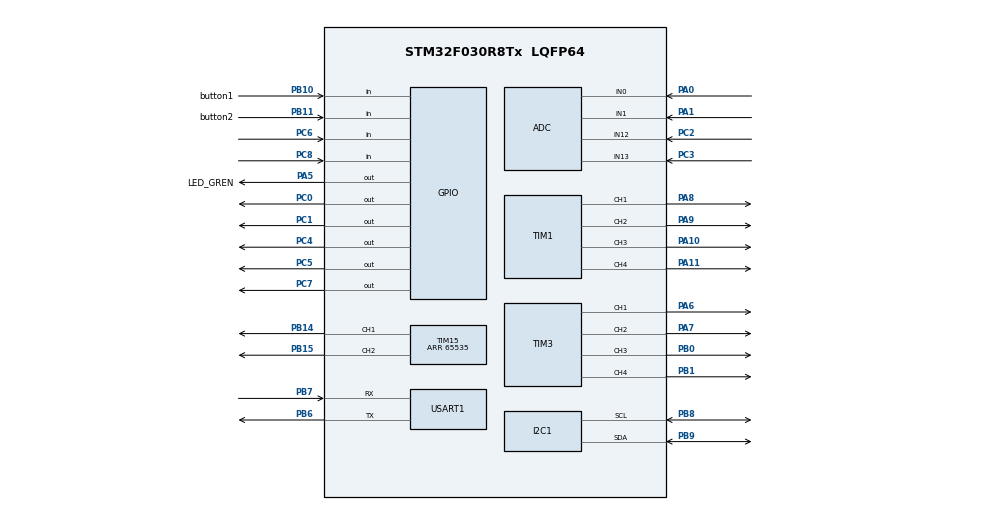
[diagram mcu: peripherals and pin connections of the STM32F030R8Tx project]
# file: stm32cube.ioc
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FREERTOS.Tasks01=task_1,24,128,task_1_function,Default,NULL,Dynamic,NULL,NULL;task_2,16,128,task_2_function,Default,NULL,Dynamic,NULL,NULL
Mcu.Family=STM32F0
Mcu.Name=STM32F030R8Tx
Mcu.Package=LQFP64
NVIC.TIM6_IRQn=true\:3\:0\:false\:false\:true\:false\:false\:true\:true
NVIC.TimeBase=TIM6_IRQn
NVIC.TimeBaseIP=TIM6
PA0.Mode=IN0
PA0.Signal=ADC_IN0
PA1.Mode=IN1
PA1.Signal=ADC_IN1
PA10.Signal=S_TIM1_CH3
PA11.Signal=S_TIM1_CH4
PA13.Mode=Serial_Wire
PA13.Signal=SYS_SWDIO
PA14.Mode=Serial_Wire
PA14.Signal=SYS_SWCLK
PA2.Signal=USART2_TX
PA3.Signal=USART2_RX
PA5.GPIO_Label=LED_GREN
PA5.Signal=GPIO_Output
PA6.Signal=S_TIM3_CH1
PA7.Signal=S_TIM3_CH2
PA8.Signal=S_TIM1_CH1
PA9.Signal=S_TIM1_CH2
PB0.Signal=S_TIM3_CH3
PB1.Signal=S_TIM3_CH4
PB10.GPIO_Label=button1
PB10.Signal=GPIO_Input
PB11.GPIO_Label=button2
PB11.Signal=GPIO_Input
PB14.Signal=S_TIM15_CH1
PB15.Signal=S_TIM15_CH2
PB6.Mode=Asynchronous
PB6.Signal=USART1_TX
PB7.Mode=Asynchronous
PB7.Signal=USART1_RX
PB8.Mode=I2C
PB8.Signal=I2C1_SCL
PB9.Mode=I2C
PB9.Signal=I2C1_SDA
PC0.Signal=GPIO_Output
PC1.Signal=GPIO_Output
PC2.Mode=IN12
PC2.Signal=ADC_IN12
PC3.Mode=IN13
PC3.Signal=ADC_IN13
PC4.Signal=GPIO_Output
PC5.Signal=GPIO_Output
PC6.Signal=GPIO_Input
PC7.Signal=GPIO_Output
PC8.Signal=GPIO_Input
ProjectManager.HeapSize=0x200
ProjectManager.StackSize=0x400
ProjectManager.TargetToolchain=Makefile
SH.S_TIM15_CH1.0=TIM15_CH1,PWM Generation1 CH1
SH.S_TIM15_CH2.0=TIM15_CH2,PWM Generation2 CH2
SH.S_TIM1_CH1.0=TIM1_CH1,PWM Generation1 CH1
SH.S_TIM1_CH2.0=TIM1_CH2,PWM Generation2 CH2
SH.S_TIM1_CH3.0=TIM1_CH3,PWM Generation3 CH3
SH.S_TIM1_CH4.0=TIM1_CH4,PWM Generation4 CH4
SH.S_TIM3_CH1.0=TIM3_CH1,PWM Generation1 CH1
SH.S_TIM3_CH2.0=TIM3_CH2,PWM Generation2 CH2
SH.S_TIM3_CH3.0=TIM3_CH3,PWM Generation3 CH3
SH.S_TIM3_CH4.0=TIM3_CH4,PWM Generation4 CH4
TIM1.Channel-PWM\ Generation1\ CH1=TIM_CHANNEL_1
TIM1.Channel-PWM\ Generation2\ CH2=TIM_CHANNEL_2
TIM1.Channel-PWM\ Generation3\ CH3=TIM_CHANNEL_3
TIM1.Channel-PWM\ Generation4\ CH4=TIM_CHANNEL_4
TIM15.Channel-PWM\ Generation1\ CH1=TIM_CHANNEL_1
TIM15.Channel-PWM\ Generation2\ CH2=TIM_CHANNEL_2
TIM15.Period=65535
TIM3.Channel-PWM\ Generation1\ CH1=TIM_CHANNEL_1
TIM3.Channel-PWM\ Generation2\ CH2=TIM_CHANNEL_2
TIM3.Channel-PWM\ Generation3\ CH3=TIM_CHANNEL_3
TIM3.Channel-PWM\ Generation4\ CH4=TIM_CHANNEL_4
USART1.VirtualMode-Asynchronous=VM_ASYNC
VP_FREERTOS_VS_CMSIS_V2.Mode=CMSIS_V2
VP_SYS_VS_tim6.Mode=TIM6
VP_TIM15_VS_ClockSourceINT.Mode=Internal
board=custom

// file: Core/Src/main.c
/* USER CODE BEGIN Header */
/**
  ******************************************************************************
  * @file           : main.c
  * @brief          : Main program body
  ******************************************************************************
  * @attention
  *
  * Copyright (c) 2024 STMicroelectronics.
  * All rights reserved.
  *
  * This software is licensed under terms that can be found in the LICENSE file
  * in the root directory of this software component.
  * If no LICENSE file comes with this software, it is provided AS-IS.
  *
  ******************************************************************************
  */
/* USER CODE END Header */
#include "main.h"
#include "cmsis_os.h"

ADC_HandleTypeDef hadc;

I2C_HandleTypeDef hi2c1;

TIM_HandleTypeDef htim1;
TIM_HandleTypeDef htim3;
TIM_HandleTypeDef htim15;

UART_HandleTypeDef huart1;

/* Definitions for task_1 */
osThreadId_t task_1Handle;
const osThreadAttr_t task_1_attributes = {
  .name = "task_1",
  .stack_size = 128 * 4,
  .priority = (osPriority_t) osPriorityNormal,
};
/* Definitions for task_2 */
osThreadId_t task_2Handle;
const osThreadAttr_t task_2_attributes = {
  .name = "task_2",
  .stack_size = 128 * 4,
  .priority = (osPriority_t) osPriorityBelowNormal,
};

void SystemClock_Config(void);
static void MX_GPIO_Init(void);
static void MX_ADC_Init(void);
static void MX_TIM3_Init(void);
static void MX_TIM15_Init(void);
static void MX_I2C1_Init(void);
static void MX_TIM1_Init(void);
static void MX_USART1_UART_Init(void);
void task_1_function(void *argument);
void task_2_function(void *argument);

int main(void)
{

  /* MCU Configuration--------------------------------------------------------*/

  /* Reset of all peripherals, Initializes the Flash interface and the Systick. */
  HAL_Init();

  /* Configure the system clock */
  SystemClock_Config();

  /* Initialize all configured peripherals */
  MX_GPIO_Init();
  MX_ADC_Init();
  MX_TIM3_Init();
  MX_TIM15_Init();
  MX_I2C1_Init();
  MX_TIM1_Init();
  MX_USART1_UART_Init();

  /* Init scheduler */
  osKernelInitialize();

  /* Create the thread(s) */
  /* creation of task_1 */
  task_1Handle = osThreadNew(task_1_function, NULL, &task_1_attributes);

  /* creation of task_2 */
  task_2Handle = osThreadNew(task_2_function, NULL, &task_2_attributes);

  /* Start scheduler */
  osKernelStart();

  /* We should never get here as control is now taken by the scheduler */
  /* Infinite loop */
  while (1)
  {

  }
}

void SystemClock_Config(void)
{
  RCC_OscInitTypeDef RCC_OscInitStruct = {0};
  RCC_ClkInitTypeDef RCC_ClkInitStruct = {0};
  RCC_PeriphCLKInitTypeDef PeriphClkInit = {0};

  /** Initializes the RCC Oscillators according to the specified parameters
  * in the RCC_OscInitTypeDef structure.
  */
  RCC_OscInitStruct.OscillatorType = RCC_OSCILLATORTYPE_HSI|RCC_OSCILLATORTYPE_HSI14;
  RCC_OscInitStruct.HSIState = RCC_HSI_ON;
  RCC_OscInitStruct.HSI14State = RCC_HSI14_ON;
  RCC_OscInitStruct.HSICalibrationValue = RCC_HSICALIBRATION_DEFAULT;
  RCC_OscInitStruct.HSI14CalibrationValue = 16;
  RCC_OscInitStruct.PLL.PLLState = RCC_PLL_NONE;
  if (HAL_RCC_OscConfig(&RCC_OscInitStruct) != HAL_OK)
  {
    Error_Handler();
  }

  /** Initializes the CPU, AHB and APB buses clocks
  */
  RCC_ClkInitStruct.ClockType = RCC_CLOCKTYPE_HCLK|RCC_CLOCKTYPE_SYSCLK
                              |RCC_CLOCKTYPE_PCLK1;
  RCC_ClkInitStruct.SYSCLKSource = RCC_SYSCLKSOURCE_HSI;
  RCC_ClkInitStruct.AHBCLKDivider = RCC_SYSCLK_DIV1;
  RCC_ClkInitStruct.APB1CLKDivider = RCC_HCLK_DIV1;

  if (HAL_RCC_ClockConfig(&RCC_ClkInitStruct, FLASH_LATENCY_0) != HAL_OK)
  {
    Error_Handler();
  }
  PeriphClkInit.PeriphClockSelection = RCC_PERIPHCLK_USART1|RCC_PERIPHCLK_I2C1;
  PeriphClkInit.Usart1ClockSelection = RCC_USART1CLKSOURCE_PCLK1;
  PeriphClkInit.I2c1ClockSelection = RCC_I2C1CLKSOURCE_HSI;
  if (HAL_RCCEx_PeriphCLKConfig(&PeriphClkInit) != HAL_OK)
  {
    Error_Handler();
  }
}

static void MX_ADC_Init(void)
{

  ADC_ChannelConfTypeDef sConfig = {0};

  /** Configure the global features of the ADC (Clock, Resolution, Data Alignment and number of conversion)
  */
  hadc.Instance = ADC1;
  hadc.Init.ClockPrescaler = ADC_CLOCK_ASYNC_DIV1;
  hadc.Init.Resolution = ADC_RESOLUTION_12B;
  hadc.Init.DataAlign = ADC_DATAALIGN_RIGHT;
  hadc.Init.ScanConvMode = ADC_SCAN_DIRECTION_FORWARD;
  hadc.Init.EOCSelection = ADC_EOC_SINGLE_CONV;
  hadc.Init.LowPowerAutoWait = DISABLE;
  hadc.Init.LowPowerAutoPowerOff = DISABLE;
  hadc.Init.ContinuousConvMode = DISABLE;
  hadc.Init.DiscontinuousConvMode = DISABLE;
  hadc.Init.ExternalTrigConv = ADC_SOFTWARE_START;
  hadc.Init.ExternalTrigConvEdge = ADC_EXTERNALTRIGCONVEDGE_NONE;
  hadc.Init.DMAContinuousRequests = DISABLE;
  hadc.Init.Overrun = ADC_OVR_DATA_PRESERVED;
  if (HAL_ADC_Init(&hadc) != HAL_OK)
  {
    Error_Handler();
  }

  /** Configure for the selected ADC regular channel to be converted.
  */
  sConfig.Channel = ADC_CHANNEL_0;
  sConfig.Rank = ADC_RANK_CHANNEL_NUMBER;
  sConfig.SamplingTime = ADC_SAMPLETIME_1CYCLE_5;
  if (HAL_ADC_ConfigChannel(&hadc, &sConfig) != HAL_OK)
  {
    Error_Handler();
  }

  /** Configure for the selected ADC regular channel to be converted.
  */
  sConfig.Channel = ADC_CHANNEL_1;
  if (HAL_ADC_ConfigChannel(&hadc, &sConfig) != HAL_OK)
  {
    Error_Handler();
  }

  /** Configure for the selected ADC regular channel to be converted.
  */
  sConfig.Channel = ADC_CHANNEL_2;
  if (HAL_ADC_ConfigChannel(&hadc, &sConfig) != HAL_OK)
  {
    Error_Handler();
  }

  /** Configure for the selected ADC regular channel to be converted.
  */
  sConfig.Channel = ADC_CHANNEL_3;
  if (HAL_ADC_ConfigChannel(&hadc, &sConfig) != HAL_OK)
  {
    Error_Handler();
  }

}

static void MX_I2C1_Init(void)
{

  hi2c1.Instance = I2C1;
  hi2c1.Init.Timing = 0x2000090E;
  hi2c1.Init.OwnAddress1 = 0;
  hi2c1.Init.AddressingMode = I2C_ADDRESSINGMODE_7BIT;
  hi2c1.Init.DualAddressMode = I2C_DUALADDRESS_DISABLE;
  hi2c1.Init.OwnAddress2 = 0;
  hi2c1.Init.OwnAddress2Masks = I2C_OA2_NOMASK;
  hi2c1.Init.GeneralCallMode = I2C_GENERALCALL_DISABLE;
  hi2c1.Init.NoStretchMode = I2C_NOSTRETCH_DISABLE;
  if (HAL_I2C_Init(&hi2c1) != HAL_OK)
  {
    Error_Handler();
  }

  /** Configure Analogue filter
  */
  if (HAL_I2CEx_ConfigAnalogFilter(&hi2c1, I2C_ANALOGFILTER_ENABLE) != HAL_OK)
  {
    Error_Handler();
  }

  /** Configure Digital filter
  */
  if (HAL_I2CEx_ConfigDigitalFilter(&hi2c1, 0) != HAL_OK)
  {
    Error_Handler();
  }

}

static void MX_TIM1_Init(void)
{

  TIM_MasterConfigTypeDef sMasterConfig = {0};
  TIM_OC_InitTypeDef sConfigOC = {0};
  TIM_BreakDeadTimeConfigTypeDef sBreakDeadTimeConfig = {0};

  htim1.Instance = TIM1;
  htim1.Init.Prescaler = 0;
  htim1.Init.CounterMode = TIM_COUNTERMODE_UP;
  htim1.Init.Period = 65535;
  htim1.Init.ClockDivision = TIM_CLOCKDIVISION_DIV1;
  htim1.Init.RepetitionCounter = 0;
  htim1.Init.AutoReloadPreload = TIM_AUTORELOAD_PRELOAD_DISABLE;
  if (HAL_TIM_PWM_Init(&htim1) != HAL_OK)
  {
    Error_Handler();
  }
  sMasterConfig.MasterOutputTrigger = TIM_TRGO_RESET;
  sMasterConfig.MasterSlaveMode = TIM_MASTERSLAVEMODE_DISABLE;
  if (HAL_TIMEx_MasterConfigSynchronization(&htim1, &sMasterConfig) != HAL_OK)
  {
    Error_Handler();
  }
  sConfigOC.OCMode = TIM_OCMODE_PWM1;
  sConfigOC.Pulse = 0;
  sConfigOC.OCPolarity = TIM_OCPOLARITY_HIGH;
  sConfigOC.OCNPolarity = TIM_OCNPOLARITY_HIGH;
  sConfigOC.OCFastMode = TIM_OCFAST_DISABLE;
  sConfigOC.OCIdleState = TIM_OCIDLESTATE_RESET;
  sConfigOC.OCNIdleState = TIM_OCNIDLESTATE_RESET;
  if (HAL_TIM_PWM_ConfigChannel(&htim1, &sConfigOC, TIM_CHANNEL_1) != HAL_OK)
  {
    Error_Handler();
  }
  if (HAL_TIM_PWM_ConfigChannel(&htim1, &sConfigOC, TIM_CHANNEL_2) != HAL_OK)
  {
    Error_Handler();
  }
  if (HAL_TIM_PWM_ConfigChannel(&htim1, &sConfigOC, TIM_CHANNEL_3) != HAL_OK)
  {
    Error_Handler();
  }
  if (HAL_TIM_PWM_ConfigChannel(&htim1, &sConfigOC, TIM_CHANNEL_4) != HAL_OK)
  {
    Error_Handler();
  }
  sBreakDeadTimeConfig.OffStateRunMode = TIM_OSSR_DISABLE;
  sBreakDeadTimeConfig.OffStateIDLEMode = TIM_OSSI_DISABLE;
  sBreakDeadTimeConfig.LockLevel = TIM_LOCKLEVEL_OFF;
  sBreakDeadTimeConfig.DeadTime = 0;
  sBreakDeadTimeConfig.BreakState = TIM_BREAK_DISABLE;
  sBreakDeadTimeConfig.BreakPolarity = TIM_BREAKPOLARITY_HIGH;
  sBreakDeadTimeConfig.AutomaticOutput = TIM_AUTOMATICOUTPUT_DISABLE;
  if (HAL_TIMEx_ConfigBreakDeadTime(&htim1, &sBreakDeadTimeConfig) != HAL_OK)
  {
    Error_Handler();
  }
  HAL_TIM_MspPostInit(&htim1);

}

static void MX_TIM3_Init(void)
{

  TIM_MasterConfigTypeDef sMasterConfig = {0};
  TIM_OC_InitTypeDef sConfigOC = {0};

  htim3.Instance = TIM3;
  htim3.Init.Prescaler = 0;
  htim3.Init.CounterMode = TIM_COUNTERMODE_UP;
  htim3.Init.Period = 65535;
  htim3.Init.ClockDivision = TIM_CLOCKDIVISION_DIV1;
  htim3.Init.AutoReloadPreload = TIM_AUTORELOAD_PRELOAD_DISABLE;
  if (HAL_TIM_PWM_Init(&htim3) != HAL_OK)
  {
    Error_Handler();
  }
  sMasterConfig.MasterOutputTrigger = TIM_TRGO_RESET;
  sMasterConfig.MasterSlaveMode = TIM_MASTERSLAVEMODE_DISABLE;
  if (HAL_TIMEx_MasterConfigSynchronization(&htim3, &sMasterConfig) != HAL_OK)
  {
    Error_Handler();
  }
  sConfigOC.OCMode = TIM_OCMODE_PWM1;
  sConfigOC.Pulse = 0;
  sConfigOC.OCPolarity = TIM_OCPOLARITY_HIGH;
  sConfigOC.OCFastMode = TIM_OCFAST_DISABLE;
  if (HAL_TIM_PWM_ConfigChannel(&htim3, &sConfigOC, TIM_CHANNEL_1) != HAL_OK)
  {
    Error_Handler();
  }
  if (HAL_TIM_PWM_ConfigChannel(&htim3, &sConfigOC, TIM_CHANNEL_2) != HAL_OK)
  {
    Error_Handler();
  }
  if (HAL_TIM_PWM_ConfigChannel(&htim3, &sConfigOC, TIM_CHANNEL_3) != HAL_OK)
  {
    Error_Handler();
  }
  if (HAL_TIM_PWM_ConfigChannel(&htim3, &sConfigOC, TIM_CHANNEL_4) != HAL_OK)
  {
    Error_Handler();
  }
  HAL_TIM_MspPostInit(&htim3);

}

static void MX_TIM15_Init(void)
{

  TIM_ClockConfigTypeDef sClockSourceConfig = {0};
  TIM_MasterConfigTypeDef sMasterConfig = {0};
  TIM_OC_InitTypeDef sConfigOC = {0};
  TIM_BreakDeadTimeConfigTypeDef sBreakDeadTimeConfig = {0};

  htim15.Instance = TIM15;
  htim15.Init.Prescaler = 0;
  htim15.Init.CounterMode = TIM_COUNTERMODE_UP;
  htim15.Init.Period = 65535;
  htim15.Init.ClockDivision = TIM_CLOCKDIVISION_DIV1;
  htim15.Init.RepetitionCounter = 0;
  htim15.Init.AutoReloadPreload = TIM_AUTORELOAD_PRELOAD_DISABLE;
  if (HAL_TIM_Base_Init(&htim15) != HAL_OK)
  {
    Error_Handler();
  }
  sClockSourceConfig.ClockSource = TIM_CLOCKSOURCE_INTERNAL;
  if (HAL_TIM_ConfigClockSource(&htim15, &sClockSourceConfig) != HAL_OK)
  {
    Error_Handler();
  }
  if (HAL_TIM_PWM_Init(&htim15) != HAL_OK)
  {
    Error_Handler();
  }
  sMasterConfig.MasterOutputTrigger = TIM_TRGO_RESET;
  sMasterConfig.MasterSlaveMode = TIM_MASTERSLAVEMODE_DISABLE;
  if (HAL_TIMEx_MasterConfigSynchronization(&htim15, &sMasterConfig) != HAL_OK)
  {
    Error_Handler();
  }
  sConfigOC.OCMode = TIM_OCMODE_PWM1;
  sConfigOC.Pulse = 0;
  sConfigOC.OCPolarity = TIM_OCPOLARITY_HIGH;
  sConfigOC.OCNPolarity = TIM_OCNPOLARITY_HIGH;
  sConfigOC.OCFastMode = TIM_OCFAST_DISABLE;
  sConfigOC.OCIdleState = TIM_OCIDLESTATE_RESET;
  sConfigOC.OCNIdleState = TIM_OCNIDLESTATE_RESET;
  if (HAL_TIM_PWM_ConfigChannel(&htim15, &sConfigOC, TIM_CHANNEL_1) != HAL_OK)
  {
    Error_Handler();
  }
  if (HAL_TIM_PWM_ConfigChannel(&htim15, &sConfigOC, TIM_CHANNEL_2) != HAL_OK)
  {
    Error_Handler();
  }
  sBreakDeadTimeConfig.OffStateRunMode = TIM_OSSR_DISABLE;
  sBreakDeadTimeConfig.OffStateIDLEMode = TIM_OSSI_DISABLE;
  sBreakDeadTimeConfig.LockLevel = TIM_LOCKLEVEL_OFF;
  sBreakDeadTimeConfig.DeadTime = 0;
  sBreakDeadTimeConfig.BreakState = TIM_BREAK_DISABLE;
  sBreakDeadTimeConfig.BreakPolarity = TIM_BREAKPOLARITY_HIGH;
  sBreakDeadTimeConfig.AutomaticOutput = TIM_AUTOMATICOUTPUT_DISABLE;
  if (HAL_TIMEx_ConfigBreakDeadTime(&htim15, &sBreakDeadTimeConfig) != HAL_OK)
  {
    Error_Handler();
  }
  HAL_TIM_MspPostInit(&htim15);

}

static void MX_USART1_UART_Init(void)
{

  huart1.Instance = USART1;
  huart1.Init.BaudRate = 38400;
  huart1.Init.WordLength = UART_WORDLENGTH_8B;
  huart1.Init.StopBits = UART_STOPBITS_1;
  huart1.Init.Parity = UART_PARITY_NONE;
  huart1.Init.Mode = UART_MODE_TX_RX;
  huart1.Init.HwFlowCtl = UART_HWCONTROL_NONE;
  huart1.Init.OverSampling = UART_OVERSAMPLING_16;
  huart1.Init.OneBitSampling = UART_ONE_BIT_SAMPLE_DISABLE;
  huart1.AdvancedInit.AdvFeatureInit = UART_ADVFEATURE_NO_INIT;
  if (HAL_UART_Init(&huart1) != HAL_OK)
  {
    Error_Handler();
  }

}

static void MX_GPIO_Init(void)
{
  GPIO_InitTypeDef GPIO_InitStruct = {0};

  /* GPIO Ports Clock Enable */
  __HAL_RCC_GPIOC_CLK_ENABLE();
  __HAL_RCC_GPIOA_CLK_ENABLE();
  __HAL_RCC_GPIOB_CLK_ENABLE();

  /*Configure GPIO pin Output Level */
  HAL_GPIO_WritePin(GPIOC, GPIO_PIN_0|GPIO_PIN_1|GPIO_PIN_2|GPIO_PIN_3
                          |GPIO_PIN_4|GPIO_PIN_5|GPIO_PIN_7, GPIO_PIN_RESET);

  /*Configure GPIO pin Output Level */
  HAL_GPIO_WritePin(LED_GREN_GPIO_Port, LED_GREN_Pin, GPIO_PIN_RESET);

  /*Configure GPIO pins : PC0 PC1 PC2 PC3
                           PC4 PC5 PC7 */
  GPIO_InitStruct.Pin = GPIO_PIN_0|GPIO_PIN_1|GPIO_PIN_2|GPIO_PIN_3
                          |GPIO_PIN_4|GPIO_PIN_5|GPIO_PIN_7;
  GPIO_InitStruct.Mode = GPIO_MODE_OUTPUT_PP;
  GPIO_InitStruct.Pull = GPIO_NOPULL;
  GPIO_InitStruct.Speed = GPIO_SPEED_FREQ_LOW;
  HAL_GPIO_Init(GPIOC, &GPIO_InitStruct);

  /*Configure GPIO pin : LED_GREN_Pin */
  GPIO_InitStruct.Pin = LED_GREN_Pin;
  GPIO_InitStruct.Mode = GPIO_MODE_OUTPUT_PP;
  GPIO_InitStruct.Pull = GPIO_NOPULL;
  GPIO_InitStruct.Speed = GPIO_SPEED_FREQ_LOW;
  HAL_GPIO_Init(LED_GREN_GPIO_Port, &GPIO_InitStruct);

  /*Configure GPIO pins : button1_Pin button2_Pin */
  GPIO_InitStruct.Pin = button1_Pin|button2_Pin;
  GPIO_InitStruct.Mode = GPIO_MODE_INPUT;
  GPIO_InitStruct.Pull = GPIO_NOPULL;
  HAL_GPIO_Init(GPIOB, &GPIO_InitStruct);

  /*Configure GPIO pins : PC6 PC8 */
  GPIO_InitStruct.Pin = GPIO_PIN_6|GPIO_PIN_8;
  GPIO_InitStruct.Mode = GPIO_MODE_INPUT;
  GPIO_InitStruct.Pull = GPIO_NOPULL;
  HAL_GPIO_Init(GPIOC, &GPIO_InitStruct);

}

void task_1_function(void *argument)
{
  /* USER CODE BEGIN 5 */
  /* Infinite loop */
  for(;;)
  {
      HAL_GPIO_TogglePin(LED_GREN_GPIO_Port, LED_GREN_Pin);
    osDelay(1000);
  }
  /* USER CODE END 5 */
}

void task_2_function(void *argument)
{
  for(;;)
  {
    osDelay(1);
  }
}

void HAL_TIM_PeriodElapsedCallback(TIM_HandleTypeDef *htim)
{
  if (htim->Instance == TIM6) {
    HAL_IncTick();
  }
}

void Error_Handler(void)
{
  __disable_irq();
  while (1)
  {
  }
}
